# R7FA8M1AH register map
Vendor: Renesas; Series: RA8; File version: 1.2
CPU: CM85 r0p0, little endian, MPU, FPU, VTOR, 4 interrupt priority bits
Registers are 32-bit, read-write, reset 0x0 unless marked. A register's access mark holds for its fields unless they carry their own. Offsets are from the block's base; [hi:lo] are bit positions; {n}, {i} and the like mark numbered series; 'fields as' and 'values as' point back to an identical list; <NAME> marks a mode.

## SYSC (part 1 of 2) — System Control
Base 0x4001E000
Same registers: SYSC_NS 0x5001E000
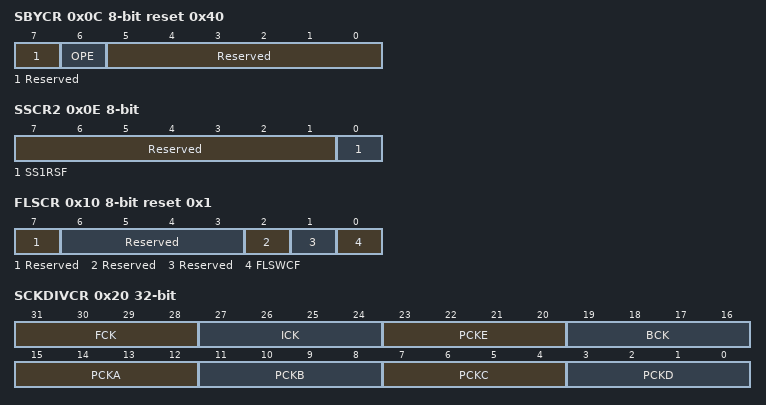
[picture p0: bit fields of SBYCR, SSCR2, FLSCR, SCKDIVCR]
0x0C SBYCR 8-bit reset 0x40 — Standby Control Register
  [7] Reserved — This bit is read as 0. The write value should be 0.
  [6] OPE — Output Port Enable
    0=In software standby mode or deep software standby mode, the address bus and bus control signals are set to the high-impedance state; 1=In software standby mode or deep software standby mode, the address bus and bus control signals retain the output state
  [5:0] Reserved — These bits are read as 000000. The write value should be 000000.
0x0E SSCR2 8-bit — Software Standby Control Register 2
  [7:1] Reserved — These bits are read as 0000000. The write value should be 0000000.
  [0] SS1RSF ro — Software Standby 1 regulator status flag
    0=After returning from Software Standby mode 1, the regulator is fully stabilized ; 1=After returning from Software Standby mode 1, the regulator is not fully stabilized 
0x10 FLSCR 8-bit reset 0x1 — Flash Standby Control Register
  [7] Reserved — This bit is read as 0. The write value should be 0.
  [6:3] Reserved — These bits are read as 0000. The write value should be 0000.
  [2] Reserved — This bit is read as 0. The write value should be 0.
  [1] Reserved — This bit is read as 0. The write value should be 0.
  [0] FLSWCF — Flash Stabilization wait completion flag
    0=Flash stabilization wait time is not completed when returning to Normal mode from Software standby mode; 1=Flash stabilization wait time is completed when returning to Normal mode from Software standby mode
0x20 SCKDIVCR — System Clock Division Control Register
  [all] fields
    0=/1 (value after reset); 1=/2; 2=/4; 3=/8; 4=/16; 5=/32; 6=/64; 8=/3; 9=/6; 10=/12
  [31:28] FCK — Flash IF Clock (FCLK) Select
  [27:24] ICK — System Clock (ICLK) Select
  [23:20] PCKE — Peripheral Module Clock E (PCLKE) Select
  [19:16] BCK — External Bus Clock (BCLK) Select
  [15:12] PCKA — Peripheral Module Clock A (PCLKA) Select
  [11:8] PCKB — Peripheral Module Clock B (PCLKB) Select
  [7:4] PCKC — Peripheral Module Clock C (PCLKC) Select
  [3:0] PCKD — Peripheral Module Clock D (PCLKD) Select
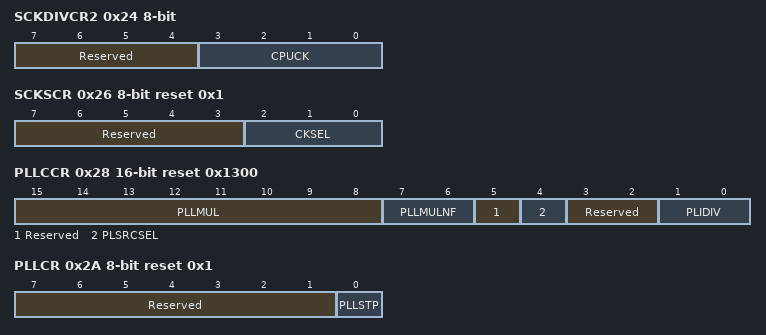
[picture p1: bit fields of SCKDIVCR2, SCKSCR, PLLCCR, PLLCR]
0x24 SCKDIVCR2 8-bit — System Clock Division Control Register 2
  [7:4] Reserved — These bits are read as 0. The write value should be 0.
  [3:0] CPUCK — CPU Clock (CPUCLK) Select
    values as the fields of SCKDIVCR
0x26 SCKSCR 8-bit reset 0x1 — System Clock Source Control Register
  [7:3] Reserved — These bits are read as 00000. The write value should be 00000.
  [2:0] CKSEL — Clock Source Select
    0=HOCO; 1=MOCO; 3=Main clock oscillator; 4=Sub-clock oscillator; 5=PLL
0x28 PLLCCR 16-bit reset 0x1300 — PLL Clock Control Register
  [15:8] PLLMUL — PLL1 Frequency Multiplication Factor Select
    25=×26 (Value after reset); 26=×27; 27=×28; 88=×89; 89=×90; 90=×91; 178=×179; 179=×180
  [7:6] PLLMULNF — PLL1 Frequency Multiplication Fractional Factor Select
    0=0.00 (Value after reset); 1=0.33 (1/3); 2=0.66 (2/3); 3=0.50 (1/2)
  [5] Reserved — This bit is read as 0. The write value should be 0.
  [4] PLSRCSEL — PLL1 Clock Source Select
    0=Main clock oscillator; 1=HOCO
  [3:2] Reserved — These bits are read as 00. The write value should be 00.
  [1:0] PLIDIV — PLL1 Input Frequency Division Ratio Select
    0=/1; 1=/2; 2=/3; 3=Setting prohibited
0x2A PLLCR 8-bit reset 0x1 — PLL Control Register
  [7:1] Reserved — These bits are read as 0000000. The write value should be 0000000.
  [0] PLLSTP — PLL1 Stop Control
    0=Operate the PLL1; 1=Stop the PLL1
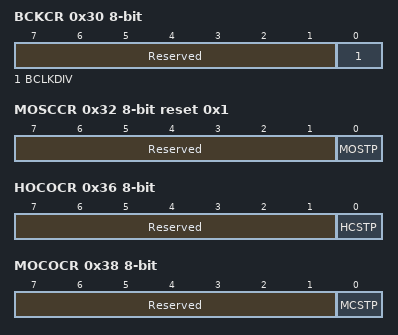
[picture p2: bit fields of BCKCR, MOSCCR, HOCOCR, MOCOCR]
0x30 BCKCR 8-bit — External Bus Clock Control Register
  [7:1] Reserved — These bits are read as 0000000. The write value should be 0000000.
  [0] BCLKDIV — BCLK Pin Output Select
    0=BCLK; 1=BCLK/2
0x32 MOSCCR 8-bit reset 0x1 — Main Clock Oscillator Control Register
  [7:1] Reserved — These bits are read as 0000000. The write value should be 0000000.
  [0] MOSTP — Main Clock Oscillator Stop
    0=Main clock oscillator is operating; 1=Main clock oscillator is stopped
0x36 HOCOCR 8-bit (reset mask 0xFE) — High-Speed On-Chip Oscillator Control Register
  [7:1] Reserved — These bits are read as 0000000. The write value should be 0000000.
  [0] HCSTP — HOCO Stop
    0=Operate the HOCO clock; 1=Stop the HOCO clock
0x38 MOCOCR 8-bit — Middle-Speed On-Chip Oscillator Control Register
  [7:1] Reserved — These bits are read as 0000000. The write value should be 0000000.
  [0] MCSTP — MOCO Stop
    0=Operate the MOCO clock; 1=Stop the MOCO clock
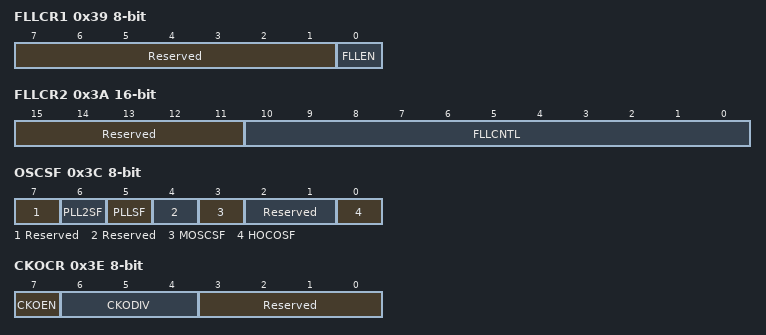
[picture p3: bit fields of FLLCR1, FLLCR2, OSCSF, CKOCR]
0x39 FLLCR1 8-bit — FLL Control Register 1
  [7:1] Reserved — These bits are read as 0000000. The write value should be 0000000.
  [0] FLLEN — FLL Enable
    0=FLL function is disabled; 1=FLL function is enabled
0x3A FLLCR2 16-bit — FLL Control Register 2
  [15:11] Reserved — These bits are read as 00000. The write value should be 00000.
  [10:0] FLLCNTL — FLL Multiplication Control
0x3C OSCSF 8-bit ro (reset mask 0xFE) — Oscillation Stabilization Flag Register
  [7] Reserved — This bit is read as 0.
  [6] PLL2SF — PLL2 Clock Oscillation Stabilization Flag
    0=The PLL2 clock is stopped or oscillation of the PLL2 clock has not yet become stable; 1=Oscillation of the PLL2 clock is stable so the clock is available for use as the system clock
  [5] PLLSF — PLL1 Clock Oscillation Stabilization Flag
    0=The PLL1 clock is stopped or oscillation of the PLL1 clock has not yet become stable; 1=Oscillation of the PLL1 clock is stable so the clock is available for use as the system clock
  [4] Reserved — This bit is read as 0.
  [3] MOSCSF — Main Clock Oscillation Stabilization Flag
    0=Main clock oscillator is stopped (MOSTP = 1) or is not yet stable; 1=Main clock oscillator is stable, so is available for use as the system clock
  [2:1] Reserved — These bits are read as 00.
  [0] HOCOSF — HOCO Clock Oscillation Stabilization FlagNOTE: The HOCOSF bit value after a reset is 1 when the OFS1.HOCOEN bit is 0. It is 0 when the OFS1.HOCOEN bit is 1.
    0=HOCO clock is stopped or is not yet stable; 1=HOCO clock is stable, so is available for use as the system clock
0x3E CKOCR 8-bit — Clock Out Control Register
  [7] CKOEN — Clock out enable
    0=Disable clock out; 1=Enable clock out
  [6:4] CKODIV — Clock out input frequency Division Select
    0=/1; 1=/2; 2=/4; 3=/8; 4=/16; 5=/32; 6=/64; 7=/128
  [3:0] Reserved — These bits are read as 0000. The write value should be 0000.
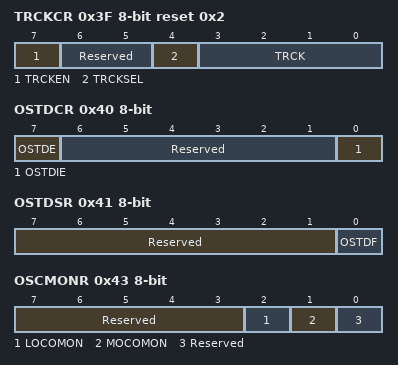
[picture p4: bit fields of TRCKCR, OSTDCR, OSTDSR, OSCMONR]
0x3F TRCKCR 8-bit reset 0x2 — Trace Clock Control Register
  [7] TRCKEN — Trace Clock operating Enable
    0=Stop; 1=Operation enable
  [6:5] Reserved — These bits are read as 00. The write value should be 00.
  [4] TRCKSEL — Trace Clock source select
    0=System clock source (value after reset); 1=HOCO (oscillation in debug mode)
  [3:0] TRCK — Trace Clock operating frequency select
0x40 OSTDCR 8-bit — Oscillation Stop Detection Control Register
  [7] OSTDE — Oscillation Stop Detection Function Enable
    0=Disable oscillation stop detection function; 1=Enable oscillation stop detection function
  [6:1] Reserved — These bits are read as 000000. The write value should be 000000.
  [0] OSTDIE — Oscillation Stop Detection Interrupt Enable
    0=Disable oscillation stop detection interrupt (do not notify the POEG); 1=Enable oscillation stop detection interrupt (notify the POEG)
0x41 OSTDSR 8-bit — Oscillation Stop Detection Status Register
  [7:1] Reserved — These bits are read as 0000000. The write value should be 0000000.
  [0] OSTDF — Oscillation Stop Detection Flag
    0=Main clock oscillation stop not detected; 1=Main clock oscillation stop detected
0x43 OSCMONR 8-bit ro — Oscillator Monitor Register
  [7:3] Reserved — These bits are read as 00000.
  [2] LOCOMON — LOCO operation monitor
    0=LOCO is set to operate; 1=LOCO is set to stop
  [1] MOCOMON — MOCO operation monitor
    0=MOCO is set to operate; 1=MOCO is set to stop
  [0] Reserved — This bit is read as 0.
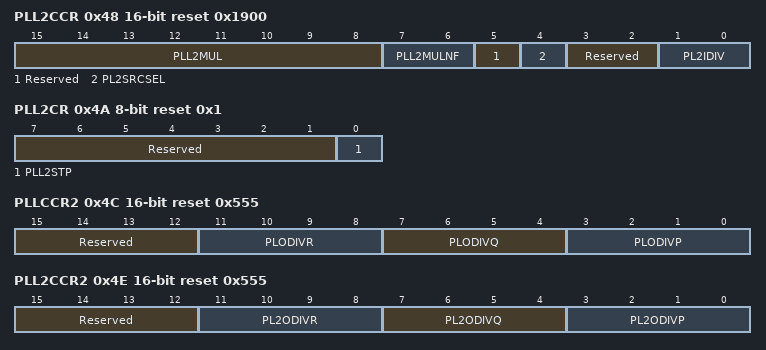
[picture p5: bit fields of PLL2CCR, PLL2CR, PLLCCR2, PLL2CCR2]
0x48 PLL2CCR 16-bit reset 0x1900 — PLL2 Clock Control Register
  [15:8] PLL2MUL — PLL2 Frequency Multiplication Factor Select
    values as PLLCCR.PLLMUL
  [7:6] PLL2MULNF — PLL2 Frequency Multiplication Fractional Factor Select
    values as PLLCCR.PLLMULNF
  [5] Reserved — This bit is read as 0. The write value should be 0.
  [4] PL2SRCSEL — PLL Clock Source Select
    0=Main clock oscillator; 1=HOCO
  [3:2] Reserved — These bits are read as 00. The write value should be 00.
  [1:0] PL2IDIV — PLL2 Input Frequency Division Ratio Select
    0=/1 (Value after reset); 1=/2; 2=/3; 3=/4
0x4A PLL2CR 8-bit reset 0x1 — PLL2 Control Register
  [7:1] Reserved — These bits are read as 0000000. The write value should be 0000000.
  [0] PLL2STP — PLL2 Stop Control
    0=Operate the PLL2; 1=Stop the PLL2
0x4C PLLCCR2 16-bit reset 0x555 — PLL Clock Control Register 2
  [15:12] Reserved — These bits are read as 0000. The write value should be 0000.
  [11:8] PLODIVR — PLL1 Output Frequency Division Ratio Select for output clock R
    0=prohibited; {v}=×1 / {v+1} (v=1..4); 5=×1 / 6 (Value after reset); 6=prohibited; 7=×1 / 8; 8=×1 / 9; {v}=prohibited (v=9..15)
  [7:4] PLODIVQ — PLL1 Output Frequency Division Ratio Select for output clock Q
    values as PLODIVR
  [3:0] PLODIVP — PLL1 Output Frequency Division Ratio Select for output clock P
    0=×1; 1=×1 / 2; 2=prohibited; 3=×1 / 4; 4=prohibited; 5=×1 / 6 (Value after reset); 6=prohibited; 7=×1 / 8; {v}=prohibited (v=8..14); 15=×1 / 16
0x4E PLL2CCR2 16-bit reset 0x555 — PLL2 Clock Control Register 2
  [15:12] Reserved — These bits are read as 0000. The write value should be 0000.
  [11:8] PL2ODIVR — PLL2 Output Frequency Division Ratio Select for output clock R
    values as PLLCCR2.PLODIVR
  [7:4] PL2ODIVQ — PLL2 Output Frequency Division Ratio Select for output clock Q
    values as PLLCCR2.PLODIVR
  [3:0] PL2ODIVP — PLL2 Output Frequency Division Ratio Select for output clock P
    values as PLLCCR2.PLODIVP
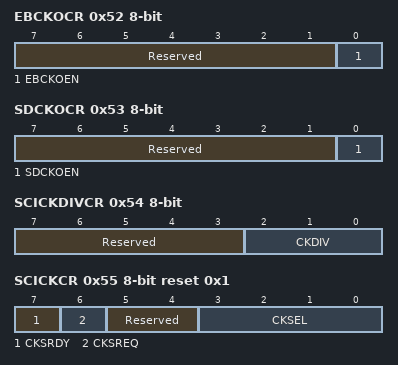
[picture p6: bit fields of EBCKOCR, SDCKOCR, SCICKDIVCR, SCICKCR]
0x52 EBCKOCR 8-bit — External Bus Clock Output Control Register
  [7:1] Reserved — These bits are read as 0000000. The write value should be 0000000.
  [0] EBCKOEN — BCLK Pin Output Control
    0=Disable EBCLK pin output (fixed high); 1=Enable EBCLK pin output
0x53 SDCKOCR 8-bit — SDRAM Clock Output Control Register
  [7:1] Reserved — These bits are read as 0000000. The write value should be 0000000.
  [0] SDCKOEN — SDCLK Pin Output Control
    0=Disable SDCLK pin output (fixed high); 1=Enable SDCLK pin output
0x54 SCICKDIVCR 8-bit — SCI clock Division control register
  [7:3] Reserved — These bits are read as 00000. The write value should be 00000.
  [2:0] CKDIV — Clock Division Select
    0=/1 (value after reset); 1=/2; 2=/4; 3=/6; 4=/8; 5=/3; 6=/5
0x55 SCICKCR 8-bit reset 0x1 — SCI clock control register
  [7] CKSRDY ro — Clock Switching Ready state flag
    0=Impossible to Switch; 1=Possible to Switch
  [6] CKSREQ — Clock Switching Request
    0=No request; 1=Request switching
  [5:4] Reserved — These bits are read as 00. The write value should be 00.
  [3:0] CKSEL — Clock Source Select
    0=HOCO; 1=MOCO (value after reset); 2=LOCO; 3=Main clock oscillator; 4=Sub-clock oscillator; 5=PLL1P; 6=PLL2P; 7=PLL1Q; 8=PLL1R; 9=PLL2Q; 10=PLL2R
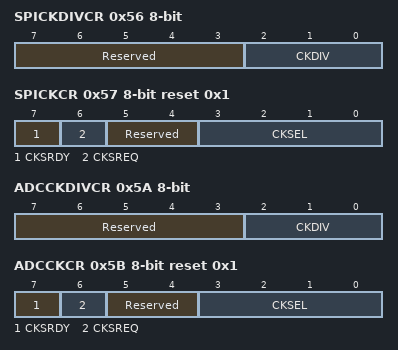
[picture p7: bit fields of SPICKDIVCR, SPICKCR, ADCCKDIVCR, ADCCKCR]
0x56 SPICKDIVCR 8-bit — SPI clock Division control register
  fields as SCICKDIVCR
0x57 SPICKCR 8-bit reset 0x1 — SPI clock control register
  fields as SCICKCR
0x5A ADCCKDIVCR 8-bit — ADC clock Division control register
  fields as SCICKDIVCR
0x5B ADCCKCR 8-bit reset 0x1 — ADC clock control register
  fields as SCICKCR
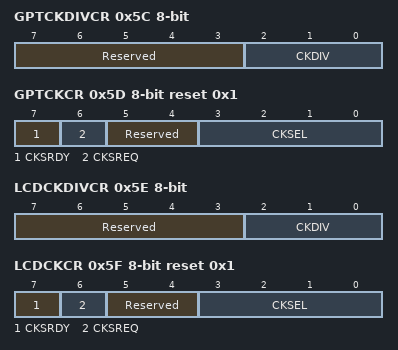
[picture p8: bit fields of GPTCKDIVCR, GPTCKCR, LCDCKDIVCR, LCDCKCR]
0x5C GPTCKDIVCR 8-bit — GPT clock Division control register
  fields as SCICKDIVCR
0x5D GPTCKCR 8-bit reset 0x1 — GPT clock control register
  fields as SCICKCR
0x5E LCDCKDIVCR 8-bit — LCD clock Division control register
  fields as SCICKDIVCR
0x5F LCDCKCR 8-bit reset 0x1 — LCD clock control register
  fields as SCICKCR
0x61 MOCOUTCR 8-bit — MOCO User Trimming Control Register
  [7:0] MOCOUTRM — MOCO User Trimming
    128=-128; 129=-127; 130=-126; 255=-1; 0=Center Code; 1=+1; 125=+125; 126=+126; 127=+127
0x62 HOCOUTCR 8-bit — HOCO User Trimming Control Register
  [7:0] HOCOUTRM — HOCO User Trimming
    values as MOCOUTCR.MOCOUTRM
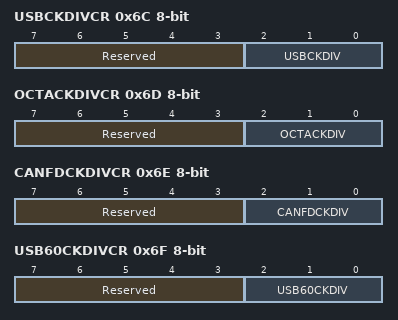
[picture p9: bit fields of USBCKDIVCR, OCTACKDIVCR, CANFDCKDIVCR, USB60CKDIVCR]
0x6C USBCKDIVCR 8-bit — USB clock Division control register
  [7:3] Reserved — These bits are read as 00000. The write value should be 00000.
  [2:0] USBCKDIV — USB clock (USBCLK) Division Select
    0=/1 (value after reset); 1=/2; 2=/4; 3=/6; 4=/8; 5=/3; 6=/5
0x6D OCTACKDIVCR 8-bit — Octal-SPI clock Division control register
  [7:3] Reserved — These bits are read as 00000. The write value should be 00000.
  [2:0] OCTACKDIV — Octal-SPI clock (OCTACLK) Division Select
    0=/1 (value after reset); 1=/2; 2=/4; 3=/6; 4=/8; 5=/3; 6=/5
0x6E CANFDCKDIVCR 8-bit — CANFD Core clock Division control register
  [7:3] Reserved — These bits are read as 00000. The write value should be 00000.
  [2:0] CANFDCKDIV — CANFD Core clock (CANFDCLK) Division Select
    0=/1 (value after reset); 1=/2; 2=/4; 3=/6; 4=/8; 5=/3; 6=/5
0x6F USB60CKDIVCR 8-bit — USB60 clock Division control register
  [7:3] Reserved — These bits are read as 00000. The write value should be 00000.
  [2:0] USB60CKDIV — USB clock (USB60CLK) Division Select
    0=/1 (value after reset); 1=/2; 2=/4; 3=/6; 4=/8; 5=/3; 6=/5
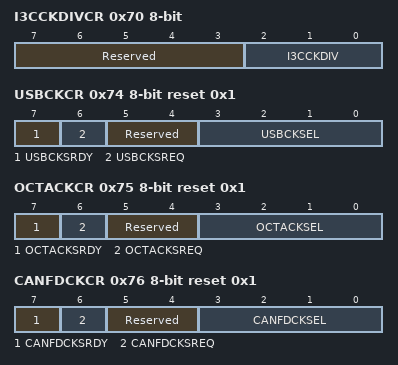
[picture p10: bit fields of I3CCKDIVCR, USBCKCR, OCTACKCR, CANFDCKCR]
0x70 I3CCKDIVCR 8-bit — I3C clock Division control register
  [7:3] Reserved — These bits are read as 00000. The write value should be 00000.
  [2:0] I3CCKDIV — I3C clock (I3CCLK) Division Select
    0=/1 (value after reset); 1=/2; 2=/4; 3=/6; 4=/8; 5=/3; 6=/5
0x74 USBCKCR 8-bit reset 0x1 — USB clock control register
  [7] USBCKSRDY — USB clock (USBCLK) Switching Ready state flag
    0=Impossible to Switch; 1=Possible to Switch
  [6] USBCKSREQ — USB clock (USBCLK) Switching Request
    0=No request; 1=Request switching
  [5:4] Reserved — These bits are read as 00. The write value should be 00.
  [3:0] USBCKSEL — USB clock (USBCLK) Source Select
    values as SCICKCR.CKSEL
0x75 OCTACKCR 8-bit reset 0x1 — Octal-SPI clock control register
  [7] OCTACKSRDY — Octal-SPI clock (OCTACLK) Switching Ready state flag
    0=Impossible to Switch; 1=Possible to Switch
  [6] OCTACKSREQ — Octal-SPI clock (OCTACLK) Switching Request
    0=No request; 1=Request switching
  [5:4] Reserved — These bits are read as 00. The write value should be 00.
  [3:0] OCTACKSEL — Octal-SPI clock (OCTACLK) Source Select
    values as SCICKCR.CKSEL
0x76 CANFDCKCR 8-bit reset 0x1 — CANFD Core clock control register
  [7] CANFDCKSRDY — CANFD Core clock (CANFDCLK) Switching Ready state flag
    0=Impossible to Switch; 1=Possible to Switch
  [6] CANFDCKSREQ — CANFD Core clock (CANFDCLK) Switching Request
    0=No request; 1=Request switching
  [5:4] Reserved — These bits are read as 00. The write value should be 00.
  [3:0] CANFDCKSEL — CANFD Core clock (CANFDCLK) Source Select
    values as SCICKCR.CKSEL
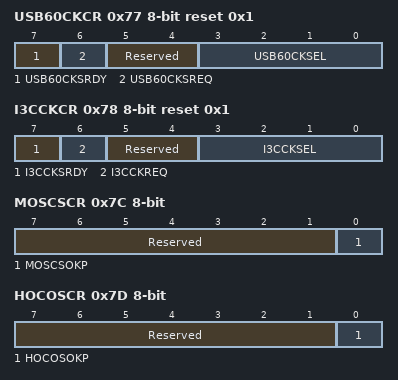
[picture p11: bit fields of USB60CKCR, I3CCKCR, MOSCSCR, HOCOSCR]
0x77 USB60CKCR 8-bit reset 0x1 — USB60 clock control register
  [7] USB60CKSRDY — USB clock (USB60CLK) Switching Ready state flag
    0=Impossible to Switch; 1=Possible to Switch
  [6] USB60CKSREQ — USB clock (USB60CLK) Switching Request
    0=No request; 1=Request switching
  [5:4] Reserved — These bits are read as 00. The write value should be 00.
  [3:0] USB60CKSEL — USB clock (USB60CLK) Source Select
    values as SCICKCR.CKSEL
0x78 I3CCKCR 8-bit reset 0x1 — I3C clock control register
  [7] I3CCKSRDY — I3C clock (I3CCLK) Switching Ready state flag
    0=Impossible to Switch; 1=Possible to Switch
  [6] I3CCKREQ — I3C clock (I3CCLK) Switching Request
    0=No request; 1=Request switching
  [5:4] Reserved — These bits are read as 00. The write value should be 00.
  [3:0] I3CCKSEL — I3C clock (I3CCLK) Source Select
    values as SCICKCR.CKSEL
0x7C MOSCSCR 8-bit — Main Clock Oscillator Standby Control Register
  [7:1] Reserved — These bits are read as 0000000. The write value should be 0000000.
  [0] MOSCSOKP — Main Clock Oscillator Standby Oscillation Keep select
    0=Disable; 1=Enable
0x7D HOCOSCR 8-bit — High-Speed On-Chip Oscillator Standby Control Register
  [7:1] Reserved — These bits are read as 0000000. The write value should be 0000000.
  [0] HOCOSOKP — HOCO Standby Oscillation Keep select
    0=Disable; 1=Enable
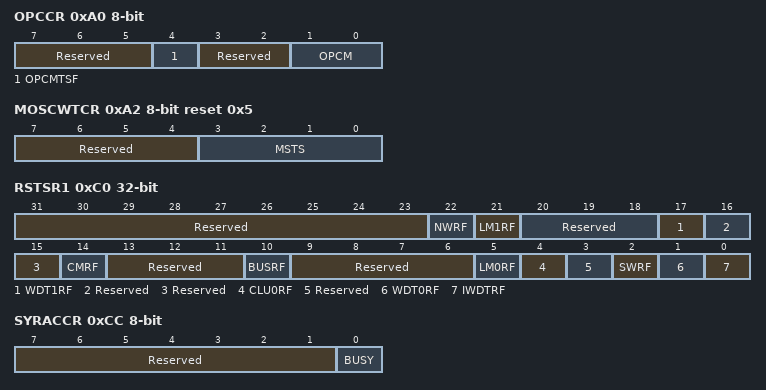
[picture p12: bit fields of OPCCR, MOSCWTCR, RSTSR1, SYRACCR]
0xA0 OPCCR 8-bit — Operating Power Control Register
  [7:5] Reserved — These bits are read as 000. The write value should be 000.
  [4] OPCMTSF ro — Operating Power Control Mode Transition Status Flag
    0=Transition completed; 1=During transition
  [3:2] Reserved — These bits are read as 00. The write value should be 00.
  [1:0] OPCM — Operating Power Control Mode Select
    0=High-speed mode; 1=Prohibited; 2=Prohibited; 3=Low-speed mode; other=others (Setting prohibited)
0xA2 MOSCWTCR 8-bit reset 0x5 — Main Clock Oscillator Wait Control Register
  [7:4] Reserved — These bits are read as 0000. The write value should be 0000.
  [3:0] MSTS — Main clock oscillator wait time setting
    0=Wait time= 11.4us (3 cycles) / 15.3us (4 cycles); 1=Wait time= 133.5us (35 cycles) / 137.3us (36 cycles); 2=Wait time= 255.6us (67 cycles) / 259.4us (68 cycles); 3=Wait time= 499.7us (131 cycles) / 503.5us (132 cycles); 4=Wait time= 988.0us (259 cycles) / 991.8us (260 cycles); 5=Wait time= 2086.6us (547 cycles) (value after reset) / 2090.5us (548 cycles) (value after reset); 6=Wait time= 4039.8us (1059 cycles) / 4043.6us (1060 cycles); 7=Wait time= 8190.2us (2147 cycles) / 8194.0us (2148 cycles); 8=Wait time= 16368.9us (4291 cycles) / 16372.7us (4292 cycles); 9=Wait time= 31139.4us (8163 cycles) / 31143.2us (8164 cycles)
0xC0 RSTSR1 (reset mask 0xFFACFFCA) — Reset Status Register 1
  [31:23] Reserved — These bits are read as 000000000. The write value should be 000000000.
  [22] NWRF write-0-clears read-modifies — Network Reset Detect FlagNOTE: Writable only to clear the flag. Confirm the value is 1 and then write 0.
    0=Network Reset not detected; 1=Network Reset detected
  [21] LM1RF write-0-clears read-modifies — Local memory 1 error Reset Detect FlagNOTE: Writable only to clear the flag. Confirm the value is 1 and then write 0.
    0=Local memory 1 error reset not detected; 1=Local memory 1 error reset detected
  [20:18] Reserved — These bits are read as 00. The write value should be 00.
  [17] WDT1RF write-0-clears read-modifies — Watchdog Timer1 Reset Detect FlagNOTE: Writable only to clear the flag. Confirm the value is 1 and then write 0.
    0=Watchdog timer1 reset not detected; 1=Watchdog timer1 reset detected
  [16] Reserved — This bit is read as 0. The write value should be 0.
  [15] Reserved — This bit is read as 0. The write value should be 0.
  [14] CMRF write-0-clears read-modifies — Common memory error Reset Detect FlagNOTE: Writable only to clear the flag. Confirm the value is 1 and then write 0.
    0=Common memory error reset not detected; 1=Common memory error reset detected
  [13:11] Reserved — These bits are read as 000. The write value should be 000.
  [10] BUSRF write-0-clears read-modifies — Bus error Reset Detect FlagNOTE: Writable only to clear the flag. Confirm the value is 1 and then write 0.
    0=Bus error reset not detected; 1=Bus error reset detected
  [9:6] Reserved — These bits are read as 0000. The write value should be 0000.
  [5] LM0RF write-0-clears read-modifies — Local memory 0 error Reset Detect FlagNOTE: Writable only to clear the flag. Confirm the value is 1 and then write 0.
    0=Local memory 0 error reset not detected; 1=Local memory 0 error reset detected
  [4] CLU0RF write-0-clears read-modifies — CPU0 Lockup Reset Detect FlagNOTE: Writable only to clear the flag. Confirm the value is 1 and then write 0.
    0=CPU0 Lockup reset not detected; 1=CPU0 Lockup reset detected
  [3] Reserved — This bit is read as 0. The write value should be 0.
  [2] SWRF write-0-clears read-modifies — Software Reset Detect FlagNOTE: Writable only to clear the flag. Confirm the value is 1 and then write 0.
    0=Software reset not detected; 1=Software reset detected
  [1] WDT0RF write-0-clears read-modifies — Watchdog Timer0 Reset Detect FlagNOTE: Writable only to clear the flag. Confirm the value is 1 and then write 0.
    0=Watchdog timer0 reset not detected; 1=Watchdog timer0 reset detected
  [0] IWDTRF write-0-clears read-modifies — Independent Watchdog Timer Reset Detect FlagNOTE: Writable only to clear the flag. Confirm the value is 1 and then write 0.
    0=Independent watchdog timer reset not detected; 1=Independent watchdog timer reset detected
0xCC SYRACCR 8-bit — System Register Access Control Register
  [7:1] Reserved — These bits are read as 0000000. The write value should be 0000000.
  [0] BUSY — Access Ready monitor
    0=Ready to read/write access; 1=Writing in progress
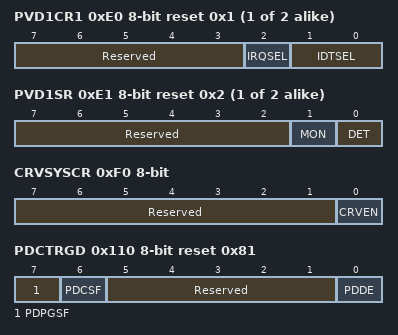
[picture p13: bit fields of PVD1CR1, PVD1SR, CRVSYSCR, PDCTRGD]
{0xDE+2i} PVD{i}CR1 (i=1..2) 8-bit reset 0x1 — Voltage Monitor {i} Circuit Control Register 1
  [7:3] Reserved — These bits are read as 00000. The write value should be 00000.
  [2] IRQSEL — Voltage Monitor Interrupt Type Select
    0=Non-maskable interrupt; 1=Maskable interrupt
  [1:0] IDTSEL — Voltage Monitor Interrupt Generation Condition Select
    0=Generate when VCC>=Vdet (rise) is detected; 1=Generate when VCC<Vdet (fall) is detected; 2=Generate when fall and rise are detected; 3=Settings prohibited
{0xDF+2i} PVD{i}SR (i=1..2) 8-bit reset 0x2 — Voltage Monitor {i} Circuit Status Register
  [7:2] Reserved — These bits are read as 000000. The write value should be 000000.
  [1] MON ro — Voltage Monitor Signal Monitor Flag
    0=VCC <= Vdet; 1=VCC > Vdet or MON bit is disabled
  [0] DET write-0-clears read-modifies — Voltage Monitor Voltage Change Detection Flag NOTE: Only 0 can be written to this bit. After writing 0 to this bit, it takes 2 system clock cycles for the bit to be read as 0.
    0=Not detected; 1=Vdet passage detection
0xF0 CRVSYSCR 8-bit — Clock Recovery System Control Register
  [7:1] Reserved — These bits are read as 0000000. The write value should be 0000000.
  [0] CRVEN — Clock Recovery Enable
    0=Disable; 1=Enable
0x110 PDCTRGD 8-bit reset 0x81 — Graphics Power Domain Control Register
  [7] PDPGSF ro — Power gating status flag
    0=Target domain is power on (not gating); 1=Target domain is power off (during Gating)
  [6] PDCSF ro — Power control status flag
    0=Power gating control is not executed (idle); 1=Power gating control is in progress
  [5:1] Reserved — These bits are read as 00000. The write value should be 00000.
  [0] PDDE — Power control enable
    0=Power on the target domain; 1=Power off the target domain
0x140 PDRAMSCR0 16-bit reset 0x7FFF — SRAM power domain Standby Control Register 0
  [15] Reserved — This bit is read as 0. The write value should be 0.
0x142 PDRAMSCR1 8-bit reset 0x3 — SRAM power domain Standby Control Register 1
  [7:2] Reserved — These bits are read as 000000. The write value should be 000000.
0x3B0 VBRSABAR 16-bit reset 0xFFE0 — VBATT Backup Register Security Attribute Boundary Address Register
  [15:0] SABA — Security Attribute Boundary Address
0x3B4 VBRPABARS 16-bit — VBATT Backup Register Privilege Attribute Boundary Address Register for Secure Region
  [15:0] PABAS — Privilege Attribute Boundary Address for Secure Region
0x3B8 VBRPABARNS 16-bit — VBATT Backup Register Privilege Attribute Boundary Address Register for Non-secure Region
  [15:0] PABANS — Privilege Attribute Boundary Address for Non-secure Region
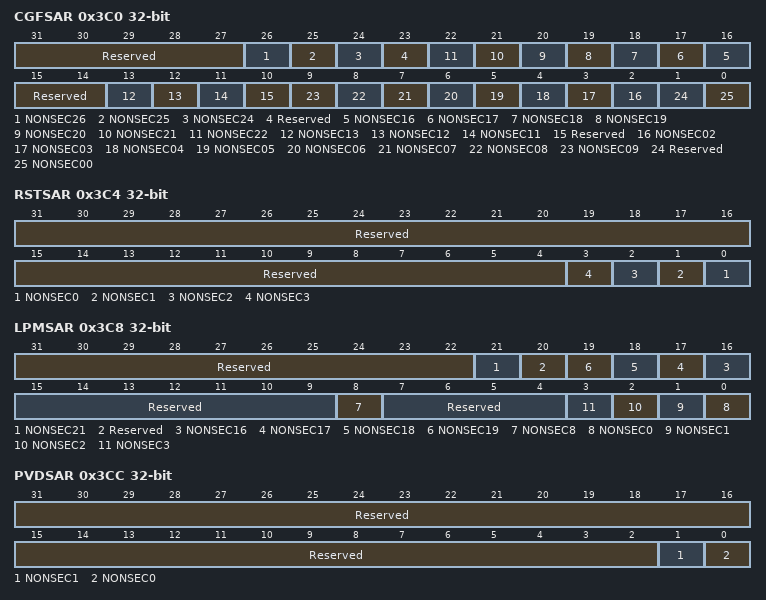
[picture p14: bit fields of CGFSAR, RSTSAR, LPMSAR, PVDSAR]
0x3C0 CGFSAR — Clock Generation Function Security Attribute Register
  [31:27] Reserved — These bits are read as 00000. The write value should be 00000.
  [26] NONSEC26 — Non-secure Attribute bit 26
    0=Secure; 1=Non-secure
  [25] NONSEC25 — Non-secure Attribute bit 25
    0=Secure; 1=Non-secure
  [24] NONSEC24 — Non-secure Attribute bit 24
    0=Secure; 1=Non-secure
  [23] Reserved — This bit is read as 0. The write value should be 0.
  [n] NONSEC{n} (n=16..22) — Non-secure Attribute bit {n}
    0=Secure; 1=Non-secure
  [15:14] Reserved — These bits are read as 00. The write value should be 00.
  [13] NONSEC13 — Non-secure Attribute bit 13
    0=Secure; 1=Non-secure
  [12] NONSEC12 — Non-secure Attribute bit 12
    0=Secure; 1=Non-secure
  [11] NONSEC11 — Non-secure Attribute bit 11
    0=Secure; 1=Non-secure
  [10] Reserved — This bit is read as 0. The write value should be 0.
  [n] NONSEC{n:02} (n=2..9) — Non-secure Attribute bit {n}
    0=Secure; 1=Non-secure
  [1] Reserved — This bit is read as 0. The write value should be 0.
  [0] NONSEC00 — Non-secure Attribute bit 0
    0=Secure; 1=Non-secure
0x3C4 RSTSAR — Reset Security Attribution Register
  [31:4] Reserved — These bits are read as 0000000000000000000000000000. The write value should be 0000000000000000000000000000.
  [n] NONSEC{n} (n=0..3) — Non-secure Attribute bit {n}
    0=Secure; 1=Non-secure
0x3C8 LPMSAR — Low Power Mode Security Attribution Register
  [31:22] Reserved — These bits are read as 0000000000. The write value should be 0000000000.
  [21] NONSEC21 — Non-secure Attribute bit 21
    0=Secure; 1=Non-secure
  [20] Reserved — This bit is read as 0. The write value should be 0.
  [n] NONSEC{n} (n=16..19) — Non-secure Attribute bit {n}
    0=Secure; 1=Non-secure
  [15:9] Reserved — These bits are read as 0000000. The write value should be 0000000.
  [8] NONSEC8 — Non-secure Attribute bit 08
    0=Secure; 1=Non-secure
  [7:4] Reserved — These bits are read as 0000. The write value should be 0000.
  [n] NONSEC{n} (n=0..3) — Non-secure Attribute bit {n:02}
    0=Secure; 1=Non-secure
0x3CC PVDSAR — Programable Voltage Detection Security Attribution Register
  [31:2] Reserved — These bits are read as 000000000000000000000000000000. The write value should be 000000000000000000000000000000.
  [1] NONSEC1 — Non-secure Attribute bit 1
    0=Secure; 1=Non-secure
  [0] NONSEC0 — Non-secure Attribute bit 0
    0=Secure; 1=Non-secure
0x3D0 BBFSAR — Battery Backup Function Security Attribute Register
  [31:5] Reserved — These bits are read as 000000000000000000000000000. The write value should be 000000000000000000000000000.
  [n] NONSEC{n} (n=0..4) — Non-secure Attribute bit {n}
    0=Secure; 1=Non-secure
0x3D8 PGCSAR — Power Gating Control Security Attribution Register
  [31:16] Reserved — These bits are read as 0000000000000000. The write value should be 0000000000000000.
  [15:7] Reserved — These bits are read as 000000000. The write value should be 000000000.
  [6] Reserved — This bit is read as 0. The write value should be 0.
  [5] Reserved — This bit is read as 0. The write value should be 0.
  [4] Reserved — This bit is read as 0. The write value should be 0.
  [3] Reserved — This bit is read as 0. The write value should be 0.
  [2] NONSEC2 — Non-secure Attribute bit 02
    0=Secure; 1=Non-secure
  [1] NONSEC1 — Non-secure Attribute bit 01
    0=Secure; 1=Non-secure
  [0] Reserved — This bit is read as 0. The write value should be 0.
